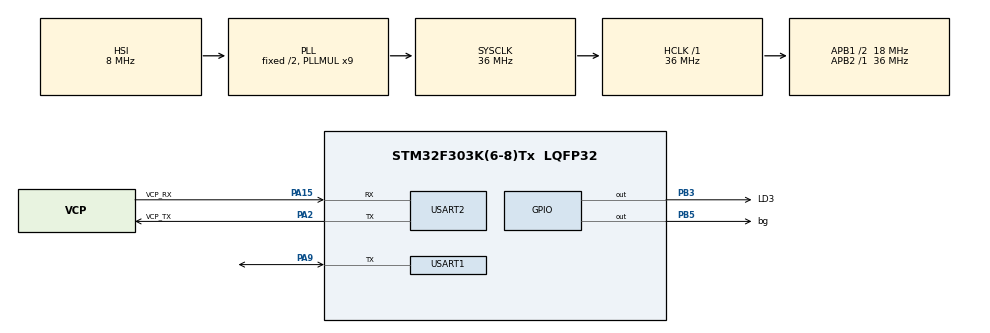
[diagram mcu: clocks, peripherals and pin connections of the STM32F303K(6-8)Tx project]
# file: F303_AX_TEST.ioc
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Mcu.Family=STM32F3
Mcu.Name=STM32F303K(6-8)Tx
Mcu.Package=LQFP32
NVIC.PriorityGroup=NVIC_PRIORITYGROUP_4
NVIC.TIM2_IRQn=true\:0\:0\:false\:false\:true\:true\:true\:true
PA13.GPIO_Label=SWDIO
PA13.Mode=Serial_Wire
PA13.Signal=SYS_JTMS-SWDIO
PA14.GPIO_Label=SWCLK
PA14.Mode=Serial_Wire
PA14.Signal=SYS_JTCK-SWCLK
PA15.GPIO_Label=VCP_RX
PA15.Mode=Asynchronous
PA15.Signal=USART2_RX
PA2.GPIO_Label=VCP_TX
PA2.Mode=Asynchronous
PA2.Signal=USART2_TX
PA9.Mode=Half_duplex(single_wire_mode)
PA9.Signal=USART1_TX
PB3.GPIO_Label=LD3
PB3.Signal=GPIO_Output
PB5.GPIO_Label=bg
PB5.Signal=GPIO_Output
PF0\ /\ OSC_IN.GPIO_Label=MCO
PF0\ /\ OSC_IN.Mode=HSE-External-Clock-Source
PF0\ /\ OSC_IN.Signal=RCC_OSC_IN
ProjectManager.HeapSize=0x200
ProjectManager.StackSize=0x400
ProjectManager.TargetToolchain=STM32CubeIDE
RCC.AHBFreq_Value=36000000
RCC.APB1CLKDivider=RCC_HCLK_DIV2
RCC.APB1Freq_Value=18000000
RCC.APB1TimFreq_Value=36000000
RCC.APB2Freq_Value=36000000
RCC.APB2TimFreq_Value=36000000
RCC.CortexFreq_Value=36000000
RCC.HCLKFreq_Value=36000000
RCC.HSE_VALUE=8000000
RCC.HSI_VALUE=8000000
RCC.PLLMUL=RCC_PLL_MUL9
RCC.SYSCLKFreq_VALUE=36000000
RCC.SYSCLKSourceVirtual=RCC_SYSCLKSOURCE_PLLCLK
TIM2.AutoReloadPreload=TIM_AUTORELOAD_PRELOAD_ENABLE
TIM2.Period=1000-1
TIM2.Prescaler=18000-1
USART1.BaudRate=250000
USART1.VirtualMode-Half_duplex(single_wire_mode)=VM_ASYNC
USART2.VirtualMode-Asynchronous=VM_ASYNC
VP_TIM2_VS_ClockSourceINT.Mode=Internal
board=NUCLEO-F303K8

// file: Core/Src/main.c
/* USER CODE BEGIN Header */
/**
  ******************************************************************************
  * @file           : main.c
  * @brief          : Main program body
  ******************************************************************************
  * @attention
  *
  * Copyright (c) 2022 STMicroelectronics.
  * All rights reserved.
  *
  * This software is licensed under terms that can be found in the LICENSE file
  * in the root directory of this software component.
  * If no LICENSE file comes with this software, it is provided AS-IS.
  *
  ******************************************************************************
  */
/* USER CODE END Header */
#include "main.h"
#include "tim.h"
#include "usart.h"
#include "gpio.h"

/* USER CODE BEGIN Includes */
#include "AX12.h"
/* USER CODE END Includes */

void SystemClock_Config(void);

int main(void)
{

  /* MCU Configuration--------------------------------------------------------*/

  /* Reset of all peripherals, Initializes the Flash interface and the Systick. */
  HAL_Init();

  /* Configure the system clock */
  SystemClock_Config();

  /* Initialize all configured peripherals */
  MX_GPIO_Init();
  MX_USART2_UART_Init();
  MX_USART1_UART_Init();
  MX_TIM2_Init();
  /* USER CODE BEGIN 2 */
  HAL_TIM_Base_Start_IT(&htim2);

  AX12 ax122;
  AX12_Init(&ax122, &huart1, 2, BR_250K);
  AX12_ReProg(&ax122, 2, BR_250K);
  AX12_LED_O_N(&ax122, 1);
  AX12_setMovingSpeed(&ax122, 10);
  //AX12_setWheelMode(&ax122);
  AX12_setRangeAngle(&ax122, 0, 180);

  /* USER CODE END 2 */

  /* Infinite loop */
  /* USER CODE BEGIN WHILE */
  while (1)
  {

	  AX12_setPosition(&ax122, 0);
	  HAL_Delay(1500);
	  AX12_setPosition(&ax122, 90);
	  HAL_Delay(1500);

    /* USER CODE END WHILE */

  }
}

void SystemClock_Config(void)
{
  RCC_OscInitTypeDef RCC_OscInitStruct = {0};
  RCC_ClkInitTypeDef RCC_ClkInitStruct = {0};
  RCC_PeriphCLKInitTypeDef PeriphClkInit = {0};

  /** Initializes the RCC Oscillators according to the specified parameters
  * in the RCC_OscInitTypeDef structure.
  */
  RCC_OscInitStruct.OscillatorType = RCC_OSCILLATORTYPE_HSI;
  RCC_OscInitStruct.HSIState = RCC_HSI_ON;
  RCC_OscInitStruct.HSICalibrationValue = RCC_HSICALIBRATION_DEFAULT;
  RCC_OscInitStruct.PLL.PLLState = RCC_PLL_ON;
  RCC_OscInitStruct.PLL.PLLSource = RCC_PLLSOURCE_HSI;
  RCC_OscInitStruct.PLL.PLLMUL = RCC_PLL_MUL9;
  if (HAL_RCC_OscConfig(&RCC_OscInitStruct) != HAL_OK)
  {
    Error_Handler();
  }

  /** Initializes the CPU, AHB and APB buses clocks
  */
  RCC_ClkInitStruct.ClockType = RCC_CLOCKTYPE_HCLK|RCC_CLOCKTYPE_SYSCLK
                              |RCC_CLOCKTYPE_PCLK1|RCC_CLOCKTYPE_PCLK2;
  RCC_ClkInitStruct.SYSCLKSource = RCC_SYSCLKSOURCE_PLLCLK;
  RCC_ClkInitStruct.AHBCLKDivider = RCC_SYSCLK_DIV1;
  RCC_ClkInitStruct.APB1CLKDivider = RCC_HCLK_DIV2;
  RCC_ClkInitStruct.APB2CLKDivider = RCC_HCLK_DIV1;

  if (HAL_RCC_ClockConfig(&RCC_ClkInitStruct, FLASH_LATENCY_1) != HAL_OK)
  {
    Error_Handler();
  }
  PeriphClkInit.PeriphClockSelection = RCC_PERIPHCLK_USART1;
  PeriphClkInit.Usart1ClockSelection = RCC_USART1CLKSOURCE_PCLK1;
  if (HAL_RCCEx_PeriphCLKConfig(&PeriphClkInit) != HAL_OK)
  {
    Error_Handler();
  }
}

void Error_Handler(void)
{
  __disable_irq();
  while (1)
  {
  }
}
